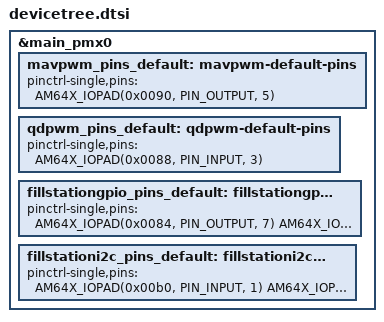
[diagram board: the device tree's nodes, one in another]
/* This file was auto-generated by TI PinMux on 11/21/2025 at 10:00:31 PM. */
/* This file should only be used as a reference. Some pins/peripherals, */
/* depending on your use case, may need additional configuration. */

&main_pmx0 {
	mavpwm_pins_default: mavpwm-default-pins {
		pinctrl-single,pins = <
			AM64X_IOPAD(0x0090, PIN_OUTPUT, 5) /* (P17) GPMC0_BE0n_CLE.EHRPWM7_A */
		>;
	};
	qdpwm_pins_default: qdpwm-default-pins {
		pinctrl-single,pins = <
			AM64X_IOPAD(0x0088, PIN_INPUT, 3) /* (R18) GPMC0_OEn_REn.EHRPWM4_A */
		>;
	};
	fillstationgpio_pins_default: fillstationgpio-default-pins {
		pinctrl-single,pins = <
			AM64X_IOPAD(0x0084, PIN_OUTPUT, 7) /* (P16) GPMC0_ADVn_ALE.GPIO0_32 */
			AM64X_IOPAD(0x008c, PIN_INPUT_PULLDOWN, 7) /* (T21) GPMC0_WEn.GPIO0_34 */
			AM64X_IOPAD(0x0094, PIN_INPUT_PULLDOWN, 7) /* (T19) GPMC0_BE1n.GPIO0_36 */
			AM64X_IOPAD(0x009c, PIN_OUTPUT, 7) /* (Y18) GPMC0_WAIT1.GPIO0_38 */
			AM64X_IOPAD(0x00a0, PIN_INPUT_PULLDOWN, 7) /* (N16) GPMC0_WPn.GPIO0_39 */
			AM64X_IOPAD(0x00a4, PIN_OUTPUT, 7) /* (N17) GPMC0_DIR.GPIO0_40 */
			AM64X_IOPAD(0x00ac, PIN_OUTPUT, 7) /* (R20) GPMC0_CSn1.GPIO0_42 */
		>;
	};
	fillstationi2c_pins_default: fillstationi2c-default-pins {
		pinctrl-single,pins = <
			AM64X_IOPAD(0x00b0, PIN_INPUT, 1) /* (P19) GPMC0_CSn2.I2C2_SCL */
			AM64X_IOPAD(0x00b4, PIN_INPUT, 1) /* (R21) GPMC0_CSn3.I2C2_SDA */
		>;
	};
};

